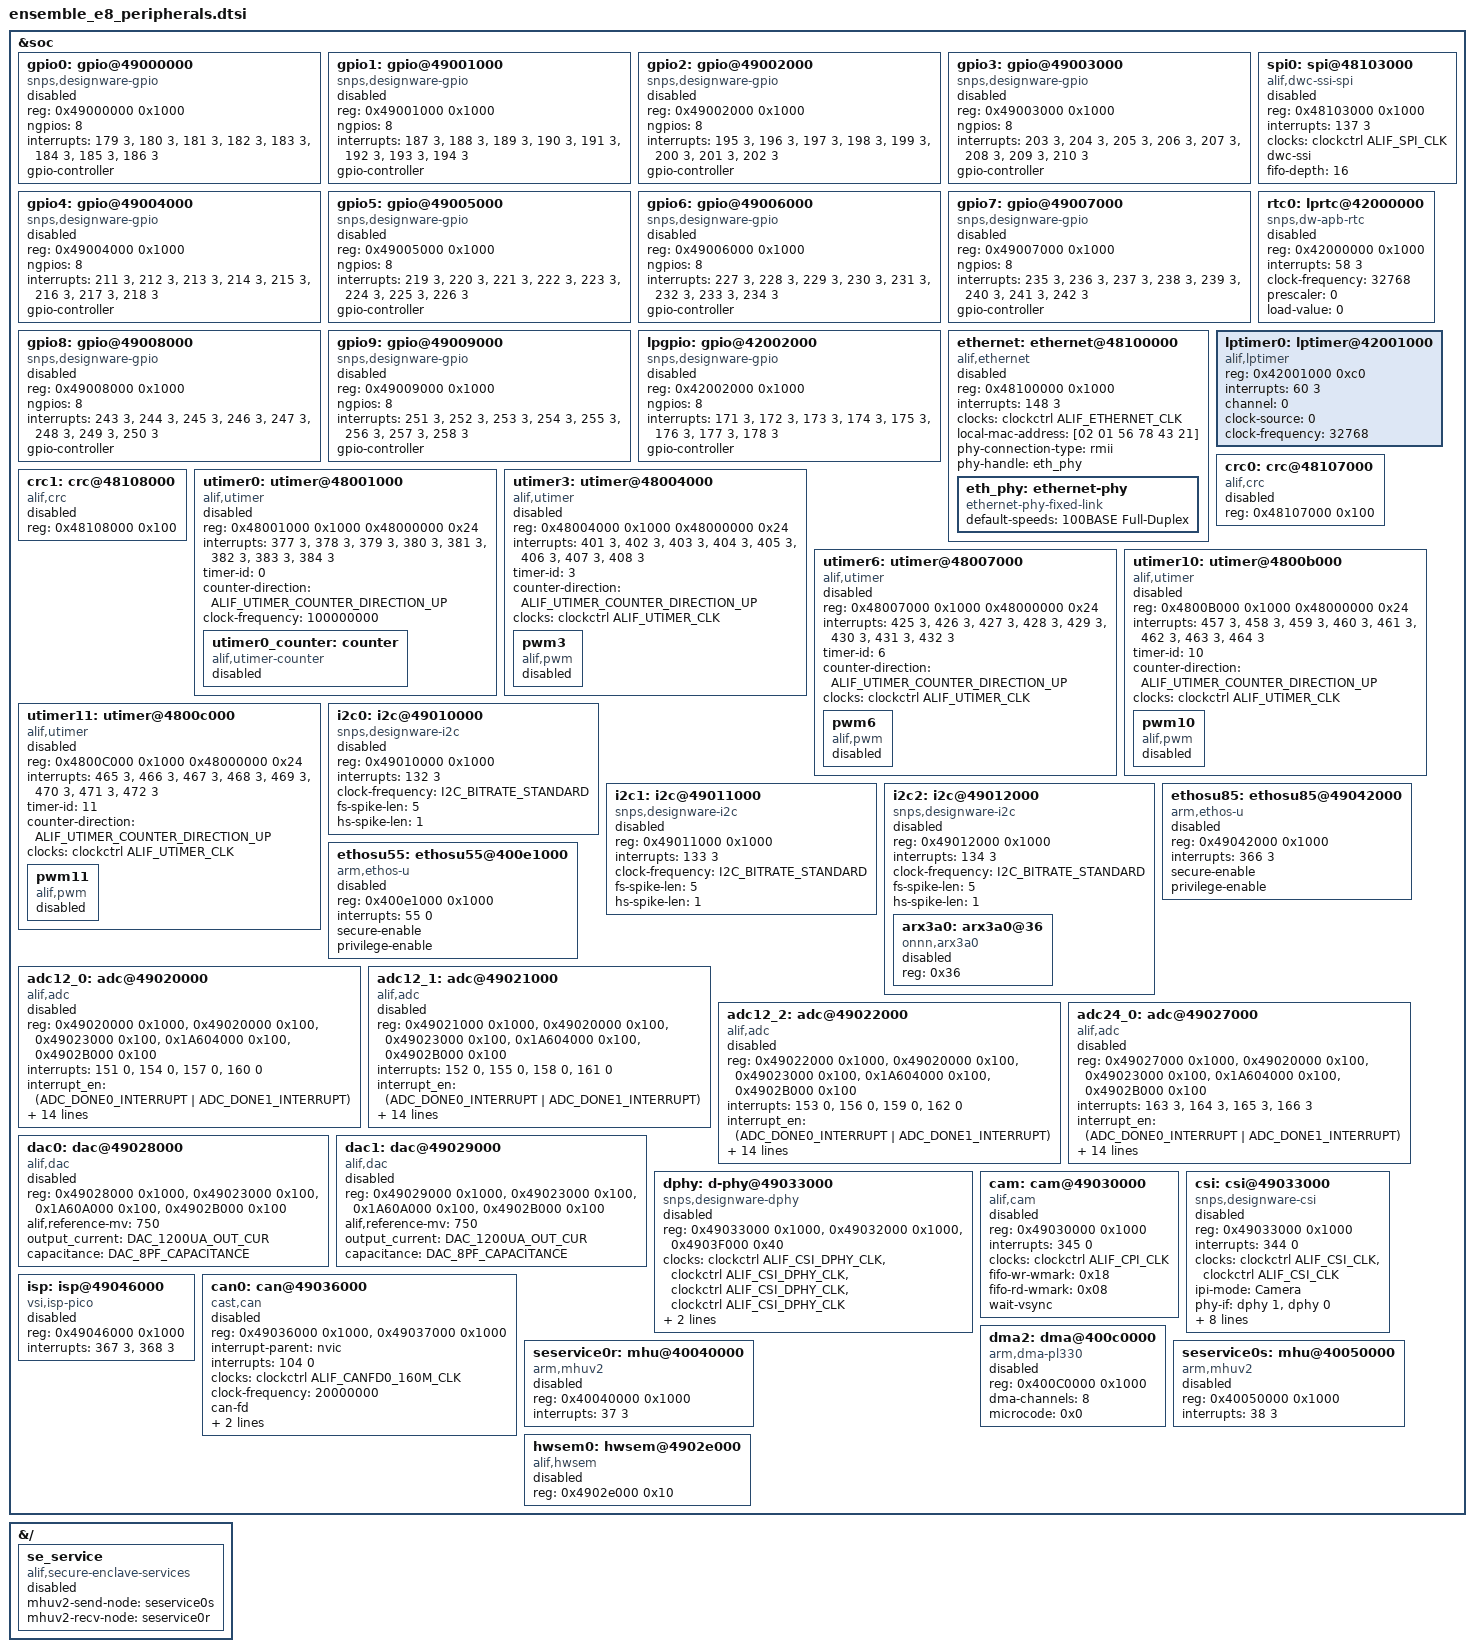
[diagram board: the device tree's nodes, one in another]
/*
 * Copyright (c) 2026 Alp Lab AB
 * SPDX-License-Identifier: Apache-2.0
 *
 * alp-sdk SoC-overlay for the Alif Ensemble E8 (AE822FA0E5597xx0).
 *
 * Upstream Zephyr v4.4's Alif SoC layer (dts/arm/alif/ensemble/) models only
 * UART + clocks + pinctrl + memory; the GPIO / I2C / SPI / Ethernet peripheral
 * nodes are absent.  Alif's peripherals are DesignWare (Synopsys) IP, for which
 * Zephyr already ships generic drivers (gpio_dw / i2c_dw / spi_dw / eth_dwmac),
 * so this overlay just *declares the nodes* with the `snps,designware-*`
 * compatibles + the SoC's reg / IRQ / clock; a board enables (status="okay")
 * the instances its carrier uses.
 *
 * reg/IRQ values are transcribed from Alif's Apache-2.0 zephyr_alif fork
 * (dts/arm/alif/ensemble/common/e1.dtsi) -- the same SoC, identical addresses.
 * The fork's ALIF_DEFAULT_IRQ_PRIORITY (not in upstream) is rendered here as a
 * literal priority 3 (the repo's default IRQ priority, matching the MHU nodes).
 *
 * Included by the alp_e1m_aen801_m55_{he,hp} boards via the alp-sdk dts_root
 * (`#include <alif/ensemble_e8_peripherals.dtsi>`).  vendor-ext, BENCH-UNVERIFIED.
 *
 * Populated (per ADR 0017 tiers): edge I2C i2c0/i2c1/i2c2 + GPIO
 * (snps,designware-* -- Tier-1 upstream-native); Ethernet (alif,ethernet glue
 * over the upstream eth_dwmac core -- Tier-1.5) + UTIMER PWM/counter
 * (alif,utimer over the Apache-2.0 hal_alif lib -- Tier-1.5); SPI0
 * (alif,dwc-ssi-spi -- Tier-2 interim).  The slave-only LPI2C0 housekeeping
 * trio (RTC/TMP/OPTIGA) is Tier-3 SE -- NO node here (see the LPI2C0 note).
 * The non-UART peripheral clock IDs upstream's alif-ensemble-clocks.h omits are
 * supplied, re-encoded for the upstream clockctrl, by the alp-sdk -ext header
 * included below.
 */

#include <zephyr/dt-bindings/clock/alif-ensemble-clocks-ext.h>
#include <zephyr/dt-bindings/timer/alif_utimer.h>
#include <zephyr/dt-bindings/i2c/i2c.h>
#include <zephyr/dt-bindings/adc/adc_alif.h>

&soc {
	/*
	 * DesignWare GPIO -- 10 general ports (gpio0..gpio9) + the LP-island
	 * port (lpgpio).  Each port is an independent 0x1000 register block with
	 * 8 pins and 8 per-pin interrupt lines.  gpio_dw needs no clocks and no
	 * pinctrl on the controller; the pad->GPIO mux is applied per-pin via the
	 * Alif pinctrl group on whichever node consumes the pin.
	 */
	gpio0: gpio@49000000 {
		compatible = "snps,designware-gpio";
		reg = <0x49000000 0x1000>;
		ngpios = <8>;
		interrupts = <179 3>, <180 3>, <181 3>, <182 3>,
			     <183 3>, <184 3>, <185 3>, <186 3>;
		gpio-controller;
		#gpio-cells = <2>;
		status = "disabled";
	};

	gpio1: gpio@49001000 {
		compatible = "snps,designware-gpio";
		reg = <0x49001000 0x1000>;
		ngpios = <8>;
		interrupts = <187 3>, <188 3>, <189 3>, <190 3>,
			     <191 3>, <192 3>, <193 3>, <194 3>;
		gpio-controller;
		#gpio-cells = <2>;
		status = "disabled";
	};

	gpio2: gpio@49002000 {
		compatible = "snps,designware-gpio";
		reg = <0x49002000 0x1000>;
		ngpios = <8>;
		interrupts = <195 3>, <196 3>, <197 3>, <198 3>,
			     <199 3>, <200 3>, <201 3>, <202 3>;
		gpio-controller;
		#gpio-cells = <2>;
		status = "disabled";
	};

	gpio3: gpio@49003000 {
		compatible = "snps,designware-gpio";
		reg = <0x49003000 0x1000>;
		ngpios = <8>;
		interrupts = <203 3>, <204 3>, <205 3>, <206 3>,
			     <207 3>, <208 3>, <209 3>, <210 3>;
		gpio-controller;
		#gpio-cells = <2>;
		status = "disabled";
	};

	gpio4: gpio@49004000 {
		compatible = "snps,designware-gpio";
		reg = <0x49004000 0x1000>;
		ngpios = <8>;
		interrupts = <211 3>, <212 3>, <213 3>, <214 3>,
			     <215 3>, <216 3>, <217 3>, <218 3>;
		gpio-controller;
		#gpio-cells = <2>;
		status = "disabled";
	};

	gpio5: gpio@49005000 {
		compatible = "snps,designware-gpio";
		reg = <0x49005000 0x1000>;
		ngpios = <8>;
		interrupts = <219 3>, <220 3>, <221 3>, <222 3>,
			     <223 3>, <224 3>, <225 3>, <226 3>;
		gpio-controller;
		#gpio-cells = <2>;
		status = "disabled";
	};

	gpio6: gpio@49006000 {
		compatible = "snps,designware-gpio";
		reg = <0x49006000 0x1000>;
		ngpios = <8>;
		interrupts = <227 3>, <228 3>, <229 3>, <230 3>,
			     <231 3>, <232 3>, <233 3>, <234 3>;
		gpio-controller;
		#gpio-cells = <2>;
		status = "disabled";
	};

	gpio7: gpio@49007000 {
		compatible = "snps,designware-gpio";
		reg = <0x49007000 0x1000>;
		ngpios = <8>;
		interrupts = <235 3>, <236 3>, <237 3>, <238 3>,
			     <239 3>, <240 3>, <241 3>, <242 3>;
		gpio-controller;
		#gpio-cells = <2>;
		status = "disabled";
	};

	gpio8: gpio@49008000 {
		compatible = "snps,designware-gpio";
		reg = <0x49008000 0x1000>;
		ngpios = <8>;
		interrupts = <243 3>, <244 3>, <245 3>, <246 3>,
			     <247 3>, <248 3>, <249 3>, <250 3>;
		gpio-controller;
		#gpio-cells = <2>;
		status = "disabled";
	};

	gpio9: gpio@49009000 {
		compatible = "snps,designware-gpio";
		reg = <0x49009000 0x1000>;
		ngpios = <8>;
		interrupts = <251 3>, <252 3>, <253 3>, <254 3>,
			     <255 3>, <256 3>, <257 3>, <258 3>;
		gpio-controller;
		#gpio-cells = <2>;
		status = "disabled";
	};

	lpgpio: gpio@42002000 {
		compatible = "snps,designware-gpio";
		reg = <0x42002000 0x1000>;
		ngpios = <8>;
		interrupts = <171 3>, <172 3>, <173 3>, <174 3>,
			     <175 3>, <176 3>, <177 3>, <178 3>;
		gpio-controller;
		#gpio-cells = <2>;
		status = "disabled";
	};

	/*
	 * LPI2C0 (0x43009000, the on-module "BRD_I2C" housekeeping bus on P7_4/P7_5,
	 * carrying OPTIGA / RV-3028 / TMP112) is DELIBERATELY NOT declared here.
	 * Per the TRM (§3.17.4) LPI2C0 is SLAVE-ONLY (the SoC is a slave at the
	 * hardcoded address 0x40); the M55 cannot master it, so an alp-sdk I2C
	 * master node would be a dead end.  That trio is ADR 0017 Tier-3: the
	 * Secure Enclave masters the bus and the reads are surfaced through Alif SE
	 * services as a portable board-info/manifest API (tasks #16/#17).  The
	 * removed alif,lpi2c driver (task #21) was the master-TX-only dead end.
	 * A next-rev board moves the housekeeping bus to a master-capable I2C
	 * (LPI2C0 -> I2C0 on P7_0/P7_1 -- task #11).
	 */

	/*
	 * Synopsys DesignWare MAC (GMAC) -- the Ensemble RMII Ethernet MAC,
	 * backing the UPSTREAM eth_dwmac core via the alp-sdk Alif glue
	 * (drivers/ethernet/eth_dwmac_alif_ensemble.c, compatible "alif,ethernet").
	 * reg/IRQ transcribed from the fork's e1.dtsi (ethernet@48100000, IRQ 148);
	 * the ALIF_ETHERNET_CLK id is synthesized in the UPSTREAM clock encoding
	 * (see alif-ensemble-clocks-ext.h -- the fork's packed value would target
	 * the wrong clock block).
	 *
	 * First bring-up uses a FIXED-LINK PHY: upstream Zephyr v4.4 ships no
	 * snps,designware-mdio driver, so the on-SoM TI DP83825I (RMII, 100/full)
	 * runs unmanaged.  A board enables this node (status="okay") + supplies
	 * pinctrl_eth (the RMII pin group) + a real local-mac-address.
	 *
	 * ADR 0017 Tier-1.5 (in-tree glue over the UPSTREAM core; kept, not
	 * fork-consumed -- the fork forked the core).  INTERIM until E8 bench.
	 *
	 * BENCH-UNVERIFIED + bench follow-up: the RMII 50 MHz ref-clock on the
	 * E1M-AEN801 comes from an on-module oscillator into P11_0 (clock-in mode);
	 * the upstream alif clock driver has NO path to program ETH_CTRL_REG's
	 * ref-clk-source select, so whether silicon needs that bit set before the
	 * MAC sees a clock is unconfirmed (do NOT invent it).
	 */
	ethernet: ethernet@48100000 {
		compatible = "alif,ethernet", "snps,designware-ethernet";
		reg = <0x48100000 0x1000>;
		interrupts = <148 3>;
		clocks = <&clockctrl ALIF_ETHERNET_CLK>;
		local-mac-address = [02 01 56 78 43 21];
		phy-connection-type = "rmii";
		phy-handle = <&eth_phy>;
		/* pinctrl-0 + pinctrl-names supplied by the enabling board overlay
		 * (RMII pin group); omitted here so the disabled node validates. */
		status = "disabled";

		eth_phy: ethernet-phy {
			compatible = "ethernet-phy-fixed-link";
			status = "okay";
			default-speeds = "100BASE Full-Duplex";
		};
	};

	/*
	 * DesignWare DWC_ssi SPI0 (AHB, always-on domain).  Driven by the alp-sdk
	 * vendored DWC-SSI driver (drivers/spi/spi_dw_alif.c, compatible
	 * "alif,dwc-ssi-spi") -- NOT upstream's "snps,designware-spi" spi_dw, which
	 * drives the DW-apb-SSI register layout (wrong CTRLR0 bit positions for this
	 * IP).  The `dwc-ssi` flag selects the DWC_ssi layout.  reg/IRQ from the
	 * fork's e1.dtsi; ALIF_SPI_CLK is a frequency-only dummy (no gate reg).
	 *
	 * ADR 0017 Tier-2 (fork-driver copy; hal_alif has no SSI lib) -- INTERIM,
	 * retires onto the fork once spi0 is repointed + bench-verified (task #21).
	 *
	 * BENCH-UNVERIFIED.  Netlist-grounded as the customer-facing edge SPI master
	 * (SoC P5_x); a board enables it (status="okay") + supplies pinctrl + the CS
	 * scheme (HW-SS vs cs-gpios is a bench unknown -- do not hard-code).  spi1
	 * (0x48104000) is the on-SoM CC3501E Wi-Fi link (GPIO-CS), not a free edge
	 * bus -- not declared here.  fifo-depth/max-xfer-size/rx-delay carry safe
	 * overridable binding defaults; override per the Alif TRM.
	 */
	spi0: spi@48103000 {
		compatible = "alif,dwc-ssi-spi";
		#address-cells = <1>;
		#size-cells = <0>;
		reg = <0x48103000 0x1000>;
		interrupts = <137 3>;
		clocks = <&clockctrl ALIF_SPI_CLK>;
		dwc-ssi;
		fifo-depth = <16>;
		status = "disabled";
	};

	/*
	 * LPRTC -- the always-on Synopsys DesignWare APB RTC at lprtc@42000000.
	 * Bound by the alp-sdk Tier-2 driver counter_dw_rtc.c (compatible
	 * "snps,dw-apb-rtc") as a Zephyr COUNTER device: a free-running 32-bit
	 * up-counter (CCVR) with ONE compare/alarm channel (CMR), clocked at
	 * 32768 Hz from the VBAT-domain LF source.  This is NOT a calendar RTC --
	 * it has no battery-backed date/time registers, so it does NOT satisfy the
	 * alp_rtc_* calendar surface as-is (the alp on-silicon RTC backend binds
	 * the Zephyr RTC *class* via the alp-rtc alias, which will not bind a
	 * counter; a counter->calendar shim backend is still TBD).  Surfaced to
	 * app code as an alp_counter via the alp-counter alias instead.
	 *
	 * reg/IRQ/clock transcribed VERBATIM from the Apache-2.0 zephyr_alif fork
	 * e1.dtsi (rtc0: lprtc@42000000; reg 0x42000000/0x1000; IRQ 58; 32768 Hz;
	 * prescaler 0; load-value 0).  The fork's ALIF_DEFAULT_IRQ_PRIORITY is
	 * rendered here as the repo's literal priority 3 (as the rest of this
	 * overlay does).
	 *
	 * CLOCK-GATE NOTE (BENCH-UNVERIFIED): the fork's SoC layer enables the
	 * LPRTC clock from VBAT when this node is okay (soc_common.c writes
	 * VBAT_LPRTC0_CLK_EN, 0x1A609010, iff rtc0 is okay).  alp-sdk builds
	 * against upstream Zephyr v4.4, whose ensemble soc.c does NOT do this
	 * write, and the driver does not write VBAT either -- so on this build path
	 * the gate is enabled by no visible code.  Confirm on the E8 bench whether
	 * the always-on VBAT domain already has it running (read CCVR; if it never
	 * advances, the VBAT gate is the cause).  Tier-2, INTERIM, task #21.
	 */
	rtc0: lprtc@42000000 {
		compatible = "snps,dw-apb-rtc";
		reg = <0x42000000 0x1000>;
		interrupts = <58 3>;
		clock-frequency = <32768>;
		prescaler = <0>;
		load-value = <0>;
		status = "disabled";
	};

	/*
	 * LPTIMER -- the always-on Alif Ensemble low-power timer at
	 * lptimer@42001000 (a DISTINCT IP from the LPRTC above and the UTIMER
	 * below).  The block holds four independent 32-bit DOWN-counters
	 * (channels 0..3), each clocked from the VBAT-domain LF source and each
	 * with its own NVIC line firing on underflow.  Bound by the alp-sdk
	 * Tier-1.5 driver counter_alif_lptimer.c (compatible "alif,lptimer") as a
	 * Zephyr COUNTER device; surfaced to app code as an alp_counter via the
	 * alp-counter alias.
	 *
	 * reg base + the four channel IRQs are transcribed VERBATIM from the Alif
	 * DFP for the E8 part AE822FA0E5597 (Device/soc/AE822FA0E5597/include/
	 * rtss_he/soc.h: LPTIMER_BASE 0x42001000, size 0xC0; IRQn LPTIMER0..3 =
	 * 60..63).  This single node selects channel 0 (IRQ 60); to use another
	 * channel, set `channel` + its matching `interrupts` (ch1=61, ch2=62,
	 * ch3=63).  IRQ priority is the repo literal 3 (as the rest of this
	 * overlay does).
	 *
	 * clock-source 0 = 32 kHz (Alif DFP sys_ctrl_lptimer.h LPTIMER_CLK_SRC);
	 * clock-frequency 32768 must match it.  These select the VBAT
	 * TIMER_CLKSEL field only; they do not change whether the count advances.
	 *
	 * CLOCK NOTE (BENCH-UNVERIFIED): the driver selects this channel's clock
	 * in the always-on VBAT TIMER_CLKSEL (0x1A609004) from the `clock-source`
	 * prop.  Whether the chosen VBAT LF source is itself running on the
	 * alp-sdk upstream-Zephyr build path is bench-TBD (read CURRENTVAL; if it
	 * never advances, the source clock is the cause).  Tier-1.5, INTERIM,
	 * task #21.
	 */
	lptimer0: lptimer@42001000 {
		compatible = "alif,lptimer";
		reg = <0x42001000 0xc0>;
		interrupts = <60 3>;
		channel = <0>;
		clock-source = <0>;       /* 0 = 32 kHz VBAT LF source */
		clock-frequency = <32768>;
	};

	/*
	 * CRC engine -- the Alif Ensemble hardware CRC accelerator (two
	 * instances).  Bound by the alp-sdk clean-room driver crc_alif.c
	 * (compatible "alif,crc"), which implements the UPSTREAM Zephyr v4.4 CRC
	 * class API (crc_begin/update/finish over struct crc_ctx).  Polled,
	 * memory-mapped block -- no interrupt line (the DFP CRC engine exposes no
	 * dedicated IRQ; only an optional DMA path this driver does not use), so
	 * the node carries reg only.
	 *
	 * reg transcribed VERBATIM (value-only, clean-room) from the Alif DFP SoC
	 * header (AE822FA0E5597 rtss_he soc.h: CRC0_BASE 0x48107000,
	 * CRC1_BASE 0x48108000; CRC_Type size 0x100).  Disabled by default; a
	 * board / example enables an instance (status = "okay").  ADR 0017
	 * Tier-1.5 (in-tree-thin over the silicon).  BENCH-UNVERIFIED, task #21.
	 */
	crc0: crc@48107000 {
		compatible = "alif,crc";
		reg = <0x48107000 0x100>;
		status = "disabled";
	};

	crc1: crc@48108000 {
		compatible = "alif,crc";
		reg = <0x48108000 0x100>;
		status = "disabled";
	};

	/*
	 * UTIMER -- Alif Universal Timer.  The parent "alif,utimer" node is an
	 * unbound container (reg = per-timer block 0x48001000+id*0x1000 + the shared
	 * global block 0x48000000); a child binds the actual class driver:
	 *   - "alif,pwm"            -> zephyr/drivers/pwm/pwm_alif_utimer.c
	 *   - "alif,utimer-counter" -> zephyr/drivers/counter/counter_alif_utimer.c
	 * reg/IRQ transcribed VERBATIM from the Apache-2.0 zephyr_alif fork e1*.dtsi
	 * (utimer0 IRQ377-384; utimer3 401-408; utimer6 425-432; utimer10 457-464;
	 * utimer11 465-472).  clock-frequency is a PLACEHOLDER tick rate (confirm vs
	 * the Alif TRM at bench bring-up; only scales us<->ticks, not register
	 * programming).  A board enables a node + its child + the alp-{pwm,counter}
	 * alias.  ADR 0017 Tier-1.5 (thin Zephyr drivers over the Apache-2.0 hal_alif
	 * alif_utimer_* register library; the fork ships UTIMER bindings only, no
	 * driver -- so there is no Tier-2 path to retire onto).  INTERIM until E8
	 * bench, then promotes to permanent.  BENCH-UNVERIFIED.
	 *
	 * utimer0 backs the portable alp_counter surface; utimer3/6/10/11 back the
	 * eight E1M PWM pads.
	 */
	utimer0: utimer@48001000 {
		compatible = "alif,utimer";
		reg = <0x48001000 0x1000 0x48000000 0x24>;
		reg-names = "timer", "global";
		interrupts = <377 3>, <378 3>, <379 3>, <380 3>,
			     <381 3>, <382 3>, <383 3>, <384 3>;
		interrupt-names = "comp_capt_a", "comp_capt_b",
				  "comp_a_buf1", "comp_a_buf2", "comp_b_buf1",
				  "comp_b_buf2", "underflow", "overflow";
		timer-id = <0>;
		counter-direction = <ALIF_UTIMER_COUNTER_DIRECTION_UP>;
		clock-frequency = <100000000>; /* placeholder; confirm vs TRM */
		status = "disabled";

		utimer0_counter: counter {
			compatible = "alif,utimer-counter";
			status = "disabled";
		};
	};

	utimer3: utimer@48004000 {
		compatible = "alif,utimer";
		reg = <0x48004000 0x1000 0x48000000 0x24>;
		reg-names = "timer", "global";
		interrupts = <401 3>, <402 3>, <403 3>, <404 3>,
			     <405 3>, <406 3>, <407 3>, <408 3>;
		timer-id = <3>;
		counter-direction = <ALIF_UTIMER_COUNTER_DIRECTION_UP>;
		clocks = <&clockctrl ALIF_UTIMER_CLK>;
		status = "disabled";

		pwm3: pwm3 {
			compatible = "alif,pwm";
			#pwm-cells = <3>;
			status = "disabled";
		};
	};

	utimer6: utimer@48007000 {
		compatible = "alif,utimer";
		reg = <0x48007000 0x1000 0x48000000 0x24>;
		reg-names = "timer", "global";
		interrupts = <425 3>, <426 3>, <427 3>, <428 3>,
			     <429 3>, <430 3>, <431 3>, <432 3>;
		timer-id = <6>;
		counter-direction = <ALIF_UTIMER_COUNTER_DIRECTION_UP>;
		clocks = <&clockctrl ALIF_UTIMER_CLK>;
		status = "disabled";

		pwm6: pwm6 {
			compatible = "alif,pwm";
			#pwm-cells = <3>;
			status = "disabled";
		};
	};

	utimer10: utimer@4800b000 {
		compatible = "alif,utimer";
		reg = <0x4800B000 0x1000 0x48000000 0x24>;
		reg-names = "timer", "global";
		interrupts = <457 3>, <458 3>, <459 3>, <460 3>,
			     <461 3>, <462 3>, <463 3>, <464 3>;
		timer-id = <10>;
		counter-direction = <ALIF_UTIMER_COUNTER_DIRECTION_UP>;
		clocks = <&clockctrl ALIF_UTIMER_CLK>;
		status = "disabled";

		pwm10: pwm10 {
			compatible = "alif,pwm";
			#pwm-cells = <3>;
			status = "disabled";
		};
	};

	utimer11: utimer@4800c000 {
		compatible = "alif,utimer";
		reg = <0x4800C000 0x1000 0x48000000 0x24>;
		reg-names = "timer", "global";
		interrupts = <465 3>, <466 3>, <467 3>, <468 3>,
			     <469 3>, <470 3>, <471 3>, <472 3>;
		timer-id = <11>;
		counter-direction = <ALIF_UTIMER_COUNTER_DIRECTION_UP>;
		clocks = <&clockctrl ALIF_UTIMER_CLK>;
		status = "disabled";

		pwm11: pwm11 {
			compatible = "alif,pwm";
			#pwm-cells = <3>;
			status = "disabled";
		};
	};

	/*
	 * Synopsys DesignWare I2C (DW_apb_i2c) -- the customer-facing EDGE I2C
	 * master buses on the E1M connector.  Bound by UPSTREAM Zephyr v4.4 i2c_dw
	 * (compatible "snps,designware-i2c"): full controller-mode read + write +
	 * repeated-START -- the master capability the slave-only LPI2C0 lacks.
	 * i2c_dw consumes only reg / interrupts / clock-frequency (= the I2C BUS
	 * speed, NOT an input clock); it does NOT read a `clocks` phandle and calls
	 * no clock_control op, so no clock-id is needed.  reg/IRQ (132/133) + the
	 * spike-filter tuning transcribed from the Apache-2.0 zephyr_alif fork
	 * e1.dtsi.  A board enables an instance (status="okay") + supplies pinctrl-0
	 * + the alp-i2cN alias.  ADR 0017 Tier-1 (upstream-native), BENCH-UNVERIFIED.
	 *
	 * NOTE: i2c0/i2c1 reach EDGE pads.  The on-module 24C128 EEPROM is on i2c2
	 * below (bridge/DNP-selected, P5_6/P5_7).  The on-module RTC/TMP112/OPTIGA
	 * sit on the slave-only LPI2C0 (P7_4/P7_5) this rev and are NOT reachable as
	 * an I2C master -- they are Tier-3 (Alif SE services); see the LPI2C0 note
	 * above + task #11 (next-rev move to a master-capable I2C).
	 */
	i2c0: i2c@49010000 {
		compatible = "snps,designware-i2c";
		#address-cells = <1>;
		#size-cells = <0>;
		reg = <0x49010000 0x1000>;
		interrupts = <132 3>;
		clock-frequency = <I2C_BITRATE_STANDARD>;
		fs-spike-len = <5>;
		hs-spike-len = <1>;
		status = "disabled";
	};

	i2c1: i2c@49011000 {
		compatible = "snps,designware-i2c";
		#address-cells = <1>;
		#size-cells = <0>;
		reg = <0x49011000 0x1000>;
		interrupts = <133 3>;
		clock-frequency = <I2C_BITRATE_STANDARD>;
		fs-spike-len = <5>;
		hs-spike-len = <1>;
		status = "disabled";
	};

	/*
	 * I2C2 -- carries the on-module 24C128 EEPROM (the Alp manifest) on the
	 * E1M-AEN801: the EEPROM's interface is selected by bridge/DNP resistors to
	 * this DesignWare master bus (SoC pins P5_6 SCL_C / P5_7 SDA_C), NOT the
	 * slave-only LPI2C0.  Full master read+write via upstream i2c_dw.  reg/IRQ
	 * are authoritative from the AE822 DFP device header (I2C2_BASE 0x49012000,
	 * I2C2_IRQ_IRQn 134).  A board enables it + supplies pinctrl_i2c2 (P5_6/7) +
	 * the alp-i2cN alias.  vendor-ext (upstream driver), BENCH-UNVERIFIED.
	 */
	i2c2: i2c@49012000 {
		compatible = "snps,designware-i2c";
		#address-cells = <1>;
		#size-cells = <0>;
		reg = <0x49012000 0x1000>;
		interrupts = <134 3>;
		clock-frequency = <I2C_BITRATE_STANDARD>;
		fs-spike-len = <5>;
		hs-spike-len = <1>;
		status = "disabled";
	};

	/*
	 * Arm Ethos-U NPUs.  The E8 (AE822) has THREE Ethos-U NPUs total -- 1x
	 * Ethos-U85 (256 MAC) + 2x Ethos-U55 (256 + 128 MAC), per the alif_e8_dk doc.
	 * All are bound by the UPSTREAM Zephyr driver (drivers/misc/ethos_u/
	 * ethos_u_arm.c, compatible "arm,ethos-u") over Arm's Apache-2.0
	 * ethos-u-core-driver (the `hal_ethos_u` Zephyr module) -- pure Tier-1
	 * (upstream + a standard Zephyr HAL module), no vendored code.  But only TWO
	 * device-tree nodes are needed, because of how the NPUs are addressed (reg/IRQ
	 * from the Apache-2.0 zephyr_alif fork: e4_e6_e8.dtsi for U85, e1.dtsi for U55):
	 *
	 *   - ethosu85@49042000 (IRQ 366): the high-end Ethos-U85, 256 MAC/cycle, in
	 *     the GLOBAL peripheral space -- one physical NPU, reachable from a core
	 *     (the RTSS-HE on this SoM) at this global address.  The E8's headline
	 *     ML/GenAI accelerator.
	 *   - ethosu55@400e1000 (IRQ 55): the Ethos-U55, but at the RTSS-core-LOCAL
	 *     address (0x400e1000 is core-private; the hal_alif driver does a
	 *     local->global remap).  The "2x U55" are NOT two addressable nodes -- they
	 *     are the per-core-local NPUs that alias to the SAME local address: the
	 *     RTSS-HP cluster's U55 is 256 MAC (alif_e8_dk HP defconfig pins
	 *     CONFIG_ARM_ETHOS_U55_256), the RTSS-HE cluster's U55 is 128 MAC.  Each
	 *     M55 only sees its OWN at 0x400e1000, so a single node suffices (exactly
	 *     as Alif's own fork dtsi does); the MAC count is core-specific, picked via
	 *     CONFIG_ARM_ETHOS_U55_{256,128} by whichever board/core builds.  (The
	 *     e1c/e1 SoC variants have ONLY this local U55 -- no U85.)
	 *
	 * A board enables the node(s) it uses + selects CONFIG_ETHOS_U +
	 * CONFIG_ETHOS_U_ARM + the per-NPU config (CONFIG_ETHOS_U85_256 /
	 * CONFIG_ARM_ETHOS_U55_*) and adds `hal_ethos_u` as a Zephyr module.  ETHOS_U_NPU
	 * is one Kconfig `choice`, so the U85 and the U55 are SEPARATE firmware builds.
	 * Inference then needs a Vela-compiled model + tensor arena.
	 *
	 * BENCH-VALIDATED at the driver level on real E8 (M55-HE) -- BOTH NPUs the HE
	 * core can reach: ethosu_init() soft-resets + registers each, device_is_ready()
	 * true.  U85 @0x49042000 NPU_REG_ID 0x20007001; HE-local U55 @0x400e1000
	 * NPU_REG_ID 0x10104201 (distinct IDs = distinct silicon).  The HP-local U55
	 * (256 MAC) is only reachable from the RTSS-HP core, so it is not exercised here.
	 */
	ethosu85: ethosu85@49042000 {
		compatible = "arm,ethos-u";
		reg = <0x49042000 0x1000>;
		interrupts = <366 3>;
		secure-enable;
		privilege-enable;
		status = "disabled";
	};

	ethosu55: ethosu55@400e1000 {
		compatible = "arm,ethos-u";
		reg = <0x400e1000 0x1000>;
		interrupts = <55 0>;
		secure-enable;
		privilege-enable;
		status = "disabled";
	};

	/*
	 * ADC -- Alif Ensemble analog-to-digital converters: three 12-bit SAR ADCs
	 * (adc12_0..2) + one 24-bit sigma-delta ADC (adc24_0).  Driven by the alp-sdk
	 * vendored fork driver (zephyr/drivers/adc/adc_alif.c, compatible "alif,adc")
	 * over the hal_alif analog_ctrl VREF library (CONFIG_ADC_ALIF selects
	 * USE_ALIF_HAL_ANALOG).  reg / reg-names / IRQs / config properties are
	 * transcribed VERBATIM from the Apache-2.0 zephyr_alif fork e1.dtsi
	 * (ensemble/common/e1.dtsi adc0..adc24):
	 *
	 *   reg-names: "adc_reg"   = per-instance ADC block (0x49020000 + id*0x1000;
	 *                            adc24 at 0x49027000)
	 *              "analog_reg"= shared ADC1 analog-control base 0x49020000
	 *              "comp_reg"  = shared comparator block 0x49023000
	 *              "aon_regs"  = always-on PMU_PERIPH block 0x1A604000
	 *              "adc_vref"  = shared ADC VREF block 0x4902B000
	 *   IRQs (done0,done1,comp_a,comp_b):
	 *              adc12_0  151,154,157,160 ; adc12_1 152,155,158,161
	 *              adc12_2  153,156,159,162 ; adc24_0 163,164,165,166
	 *   interrupt_en = DONE0|DONE1 (single-shot completion fires on DONE1).
	 *
	 * No pinctrl-0: ADC inputs are direct analog pads (the driver applies
	 * pinctrl only IF the node carries it -- IF_ENABLED on pinctrl_0).  A board
	 * enables an instance (status="okay"), sets the alp-adcN alias for the
	 * portable backend, and -- for differential / specific channels -- may add a
	 * pinctrl group per the Alif TRM.
	 *
	 * ADR 0017 Tier-2 (fork-driver copy; hal_alif has no ADC class driver) --
	 * INTERIM, retires onto the fork once the nodes are repointed +
	 * bench-verified (task #21).  BENCH-UNVERIFIED.
	 */
	adc12_0: adc@49020000 {
		compatible = "alif,adc";
		/* adc-controller.yaml (via alif,adc.yaml) requires #io-channel-cells;
		 * #address-cells/#size-cells enable the io-channels `channel@N` children. */
		#address-cells = <1>;
		#size-cells = <0>;
		#io-channel-cells = <1>;
		reg = <0x49020000 0x1000>,
		      <0x49020000 0x100>,
		      <0x49023000 0x100>,
		      <0x1A604000 0x100>,
		      <0x4902B000 0x100>;
		reg-names = "adc_reg", "analog_reg", "comp_reg", "aon_regs", "adc_vref";
		interrupts = <151 0>, <154 0>, <157 0>, <160 0>;
		interrupt-names = "done0", "done1", "comp_a", "comp_b";
		interrupt_en = <(ADC_DONE0_INTERRUPT | ADC_DONE1_INTERRUPT)>;
		comparator_threshold_a = <0x01>;
		comparator_threshold_b = <0x01>;
		comparator_threshold_comparison = "ABOVE_THRESHOLD_A_AND_B";
		sample-width = <16>;
		clock_div = <2>;
		avg_sample_num = <256>;
		shift_n_bits = <8>;
		shift_direction = "RIGHT_SHIFT";
		comparator_bias = "2.5_MS/s";
		driver_instance = "ADC_INSTANCE_ADC12_0";
		adc_channel_scan = "SINGLE_CHANNEL_SCAN";
		adc_conversion_mode = "SINGLE_SHOT_CONVERSION";
		pga_gain = "ADC_PGA_GAIN_0_DB";
		status = "disabled";
	};

	adc12_1: adc@49021000 {
		compatible = "alif,adc";
		#address-cells = <1>;
		#size-cells = <0>;
		#io-channel-cells = <1>;
		reg = <0x49021000 0x1000>,
		      <0x49020000 0x100>,
		      <0x49023000 0x100>,
		      <0x1A604000 0x100>,
		      <0x4902B000 0x100>;
		reg-names = "adc_reg", "analog_reg", "comp_reg", "aon_regs", "adc_vref";
		interrupts = <152 0>, <155 0>, <158 0>, <161 0>;
		interrupt-names = "done0", "done1", "comp_a", "comp_b";
		interrupt_en = <(ADC_DONE0_INTERRUPT | ADC_DONE1_INTERRUPT)>;
		comparator_threshold_a = <0x01>;
		comparator_threshold_b = <0x01>;
		comparator_threshold_comparison = "ABOVE_THRESHOLD_A_AND_B";
		sample-width = <16>;
		clock_div = <2>;
		avg_sample_num = <256>;
		shift_n_bits = <8>;
		shift_direction = "RIGHT_SHIFT";
		comparator_bias = "2.5_MS/s";
		driver_instance = "ADC_INSTANCE_ADC12_1";
		adc_channel_scan = "SINGLE_CHANNEL_SCAN";
		adc_conversion_mode = "SINGLE_SHOT_CONVERSION";
		pga_gain = "ADC_PGA_GAIN_0_DB";
		status = "disabled";
	};

	adc12_2: adc@49022000 {
		compatible = "alif,adc";
		#address-cells = <1>;
		#size-cells = <0>;
		#io-channel-cells = <1>;
		reg = <0x49022000 0x1000>,
		      <0x49020000 0x100>,
		      <0x49023000 0x100>,
		      <0x1A604000 0x100>,
		      <0x4902B000 0x100>;
		reg-names = "adc_reg", "analog_reg", "comp_reg", "aon_regs", "adc_vref";
		interrupts = <153 0>, <156 0>, <159 0>, <162 0>;
		interrupt-names = "done0", "done1", "comp_a", "comp_b";
		interrupt_en = <(ADC_DONE0_INTERRUPT | ADC_DONE1_INTERRUPT)>;
		comparator_threshold_a = <0x01>;
		comparator_threshold_b = <0x01>;
		comparator_threshold_comparison = "ABOVE_THRESHOLD_A_AND_B";
		sample-width = <16>;
		clock_div = <2>;
		avg_sample_num = <256>;
		shift_n_bits = <8>;
		shift_direction = "RIGHT_SHIFT";
		comparator_bias = "2.5_MS/s";
		driver_instance = "ADC_INSTANCE_ADC12_2";
		adc_channel_scan = "SINGLE_CHANNEL_SCAN";
		adc_conversion_mode = "SINGLE_SHOT_CONVERSION";
		pga_gain = "ADC_PGA_GAIN_0_DB";
		status = "disabled";
	};

	adc24_0: adc@49027000 {
		compatible = "alif,adc";
		#address-cells = <1>;
		#size-cells = <0>;
		#io-channel-cells = <1>;
		reg = <0x49027000 0x1000>,
		      <0x49020000 0x100>,
		      <0x49023000 0x100>,
		      <0x1A604000 0x100>,
		      <0x4902B000 0x100>;
		reg-names = "adc_reg", "analog_reg", "comp_reg", "aon_regs", "adc_vref";
		interrupts = <163 3>, <164 3>, <165 3>, <166 3>;
		interrupt-names = "done0", "done1", "comp_a", "comp_b";
		interrupt_en = <(ADC_DONE0_INTERRUPT | ADC_DONE1_INTERRUPT)>;
		comparator_threshold_a = <0x01>;
		comparator_threshold_b = <0x01>;
		comparator_threshold_comparison = "ABOVE_THRESHOLD_A_AND_B";
		clock_div = <2>;
		avg_sample_num = <256>;
		shift_n_bits = <8>;
		shift_direction = "RIGHT_SHIFT";
		adc24_output_rate = "1KS/s";
		adc24_bias = "8.75uA";
		driver_instance = "ADC_INSTANCE_ADC24_0";
		adc_channel_scan = "SINGLE_CHANNEL_SCAN";
		adc_conversion_mode = "SINGLE_SHOT_CONVERSION";
		pga_gain = "ADC_PGA_GAIN_0_DB";
		status = "disabled";
	};

	/*
	 * DAC -- Alif Ensemble DAC12: two 12-bit current-output DACs (dac0, dac1).
	 * Driven by the alp-sdk vendored fork driver (zephyr/drivers/dac/dac_alif.c,
	 * compatible "alif,dac") over the hal_alif analog_ctrl VREF library
	 * (CONFIG_DAC_ALIF selects USE_ALIF_HAL_ANALOG, shared with ADC_ALIF).  reg /
	 * reg-names / config properties are transcribed VERBATIM from the Apache-2.0
	 * zephyr_alif fork e1.dtsi (ensemble/common/e1.dtsi dac0/dac1):
	 *
	 *   reg-names: "dac_reg"  = per-instance DAC control block
	 *                           (dac0 0x49028000, dac1 0x49029000)
	 *              "cmp_reg"  = shared comparator block 0x49023000 (VREF control)
	 *              "vbat_reg" = always-on VBAT/analog block 0x1A60A000 (LDO+BG)
	 *              "adc_vref" = shared ADC/DAC VREF block 0x4902B000 (mapped by
	 *                           the driver ONLY under CONFIG_ANALOG_ALIASING; it is
	 *                           carried here for completeness, like the ADC nodes,
	 *                           and ignored otherwise)
	 *
	 * NO `interrupts`: the Alif DAC is a write-only IP with no IRQ -- the fork
	 * dac nodes carry none and the driver has no IRQ_CONNECT.  (Sourced from the
	 * fork driver + e1.dtsi; do NOT invent an IRQ.)
	 *
	 * NO pinctrl-0: the fork nodes reference &pinctrl_dac0/&pinctrl_dac1 (the DAC
	 * analog output pads -- dac0 = P2_2, dac1 = P2_3 per the bench notes), but
	 * those pinctrl groups are not defined in this tree.  The driver applies
	 * pinctrl only IF the node carries it (IF_ENABLED on pinctrl_0), so the nodes
	 * are left pinctrl-less; a board that needs the pad muxed adds the group per
	 * the Alif TRM.  The P2_2 / P2_3 pad mapping is a BENCH NOTE, not yet a
	 * verified pinctrl group.
	 *
	 * alif,reference-mv = DAC12 full-scale VREF in mV, consumed by the portable
	 * backend's mv->code conversion (the E8 DAC12 full-scale is the DAC VREF, NOT
	 * 3.3 V).  Set to 750: the dac_alif driver programs the DAC12 reference field
	 * to DAC12_VREF_CONT = 0x4 (dac_alif.c CMP_COMP_REG2_DAC12_VREF_CONT =
	 * (0x4U << 17), == hal_alif analog_ctrl.h:41 #define DAC12_VREF_CONT
	 * (0x4U << 17)), and the analog_ctrl.h:31-40 DAC12 reference table reads
	 * code 0x4 (100b) = 0.750 V.  So the mv->code divisor MUST be 750 to match
	 * the reference the silicon is actually programmed to (the old 900 was a
	 * wrong placeholder, not just unverified).  This is the REGISTER reference,
	 * verified vs hal_alif; the ABSOLUTE on-pad mV (load/buffer/trim) is still a
	 * TRM/bench unknown.  BENCH-UNVERIFIED (absolute pad mV).
	 *
	 * ADR 0017 Tier-2 (fork-driver copy; hal_alif has no DAC class driver) --
	 * INTERIM, retires onto the fork once the nodes are repointed +
	 * bench-verified (task #21).  BENCH-UNVERIFIED.
	 */
	dac0: dac@49028000 {
		compatible = "alif,dac";
		reg = <0x49028000 0x1000>,
		      <0x49023000 0x100>,
		      <0x1A60A000 0x100>,
		      <0x4902B000 0x100>;
		reg-names = "dac_reg", "cmp_reg", "vbat_reg", "adc_vref";
		alif,reference-mv = <750>; /* DAC12_VREF_CONT=0x4 -> 0.750 V (analog_ctrl.h:41) */
		output_current = "DAC_1200UA_OUT_CUR";
		capacitance = "DAC_8PF_CAPACITANCE";
		status = "disabled";
	};

	dac1: dac@49029000 {
		compatible = "alif,dac";
		reg = <0x49029000 0x1000>,
		      <0x49023000 0x100>,
		      <0x1A60A000 0x100>,
		      <0x4902B000 0x100>;
		reg-names = "dac_reg", "cmp_reg", "vbat_reg", "adc_vref";
		alif,reference-mv = <750>; /* DAC12_VREF_CONT=0x4 -> 0.750 V (analog_ctrl.h:41) */
		output_current = "DAC_1200UA_OUT_CUR";
		capacitance = "DAC_8PF_CAPACITANCE";
		status = "disabled";
	};

	/*
	 * CAMERA CAPTURE path -- CPI parallel-camera controller (cam) +
	 * DesignWare MIPI CSI-2 host bridge (csi) + DesignWare MIPI D-PHY (dphy),
	 * all driven by the alp-sdk vendored fork drivers (zephyr/drivers/video/
	 * video_alif.c "alif,cam", video_csi_dw.c "snps,designware-csi",
	 * zephyr/drivers/mipi_dphy/dphy_dw.c "snps,designware-dphy").  reg / IRQ /
	 * reg-names / clock-names are transcribed VERBATIM from the Apache-2.0
	 * zephyr_alif fork e3_e5_e7.dtsi (cam@49030000, csi@49033000) + e1.dtsi
	 * (d-phy@49033000) -- the SAME DesignWare camera IP across the Ensemble
	 * family, identical addresses on E8.
	 *
	 *   cam  : reg 0x49030000/0x1000          IRQ 345  clock-names "cam_clk"
	 *   csi  : reg 0x49033000/0x1000          IRQ 344  clock-names "csi_clk","pix_clk"
	 *   dphy : reg "csi_reg" 0x49033000/0x1000 (shared CSI base),
	 *          "dsi_reg" 0x49032000/0x1000, "expmst_reg" 0x4903f000/0x40
	 *          clock-names "pllref-clk","pllbypass-clk","tx-dphy-clk","rx-dphy-clk"
	 *
	 * CLOCKS -- FLAGGED PLACEHOLDER.  The fork drives these blocks with
	 * ALIF_CPI_CLK / ALIF_CSI_CLK / ALIF_CSI_PIX_SYST_ACLK / ALIF_MIPI_*_CLK,
	 * which exist ONLY in the fork's 7-arg clock encoding.  Per
	 * [[reference_alif_clock_encoding_fork_vs_upstream]] those packed values
	 * MUST NOT be copied onto the upstream alif,clockctrl (wrong register
	 * block).  The upstream-encoding gate/offset/parent for the camera clocks
	 * are a TRM/bench unknown and are NOT re-authored here -- a frequency-only
	 * dummy clock (ALIF_CLK(2U), the ALIF_SPI_CLK precedent) is used so the
	 * nodes are well-formed.  The drivers are now PORTED to the v4.4 video API
	 * (the ALP_VIDEO_ALIF_BROKEN gate is retired), but these camera nodes stay
	 * status="disabled" here -- a board overlay enables them -- and even then NO
	 * real clock is programmed (the dummy clock above).  Re-author the real
	 * camera clock IDs via alif-ensemble-clocks-ext.h when the stack is
	 * bench-brought-up (task #21).
	 *
	 * NO pinctrl-0: the fork cam node references &pinctrl_cam8 (the 8-bit CPI
	 * data pads), not defined in this tree; the driver applies pinctrl only IF
	 * the node carries it, so the node is left pinctrl-less (a board that wires
	 * a parallel sensor adds the group per the Alif TRM).  The CSI/MIPI path
	 * uses serial D-PHY pads (no parallel pinctrl).
	 *
	 * ADR 0017 Tier-2 (fork-driver copies; upstream + hal_alif ship no camera
	 * video / mipi_dphy drivers) -- INTERIM, retires onto the fork once the
	 * nodes are repointed + the drivers ported to the v4.4 video API +
	 * bench-verified (task #21).  Runtime frame CAPTURE is HW-blocked on this
	 * batch (no camera sensor wired).  BENCH-UNVERIFIED.
	 */
	dphy: d-phy@49033000 {
		compatible = "snps,designware-dphy";
		reg = <0x49033000 0x1000>,
		      <0x49032000 0x1000>,
		      <0x4903F000 0x40>;
		reg-names = "csi_reg", "dsi_reg", "expmst_reg";
		#dphy-cells = <1>;
		clocks = <&clockctrl ALIF_CSI_DPHY_CLK>,
			 <&clockctrl ALIF_CSI_DPHY_CLK>,
			 <&clockctrl ALIF_CSI_DPHY_CLK>,
			 <&clockctrl ALIF_CSI_DPHY_CLK>;
		clock-names = "pllref-clk", "pllbypass-clk", "tx-dphy-clk", "rx-dphy-clk";
		ref-frequency = <38400000>;
		cfg-clk-frequency = <25000000>;
		status = "disabled";
	};

	cam: cam@49030000 {
		compatible = "alif,cam";
		reg = <0x49030000 0x1000>;
		interrupts = <345 0>;
		clocks = <&clockctrl ALIF_CPI_CLK>;
		clock-names = "cam_clk";
		fifo-wr-wmark = <0x18>;
		fifo-rd-wmark = <0x08>;
		wait-vsync;
		status = "disabled";
	};

	csi: csi@49033000 {
		compatible = "snps,designware-csi";
		reg = <0x49033000 0x1000>;
		interrupts = <344 0>;
		clocks = <&clockctrl ALIF_CSI_CLK>, <&clockctrl ALIF_CSI_CLK>;
		clock-names = "csi_clk", "pix_clk";
		ipi-mode = "Camera";
		phy-if = <&dphy 1>, <&dphy 0>;
		csi-hsa = <5>;
		csi-hbp = <10>;
		csi-hsd = <280>;
		csi-hact = <560>;
		csi-vsa = <4>;
		csi-vbp = <4>;
		csi-vfp = <4>;
		csi-vact = <560>;
		status = "disabled";
	};

	/*
	 * Alif Ensemble ISP-Pico (Verisilicon ISP Nano "Pico", compatible
	 * "vsi,isp-pico"), driven by the vendored fork driver
	 * zephyr/drivers/video/isp_pico.c.  reg base + IRQs transcribed VERBATIM
	 * from the fork e4_e6_e8.dtsi (isp@49046000, IRQs 367 "isp" / 368
	 * "mi-isp").  Tier-2 OPT-IN -- the driver links the hal_alif libisp
	 * (Vivante) blob (CONFIG_VIDEO_ISP_VSI -> USE_ALIF_ISP_LIB) and is
	 * default n.  Left status="disabled": enabling it needs the libisp
	 * wrapper bumped (FLAGGED hal_alif version mismatch -- see the Kconfig)
	 * + a camera -> isp -> sink media-controller graph (bench-unknown).
	 * BENCH-UNVERIFIED.  Task #21.
	 */
	isp: isp@49046000 {
		compatible = "vsi,isp-pico";
		reg = <0x49046000 0x1000>;
		interrupts = <367 3>, <368 3>;
		interrupt-names = "isp", "mi-isp";
		status = "disabled";
	};

	/*
	 * CAN-FD controller -- CANFD0 (CAST CAN-CTRL IP, compatible "cast,can",
	 * base 0x49036000), bound by the Tier-2 fork driver
	 * zephyr/drivers/can/can_cast.c as a standard Zephyr can_* device.  Upstream
	 * Zephyr's only CAN driver is the Bosch M_CAN (can_mcan.c), whose register
	 * map does NOT match the CAST IP; hal_alif ships no CAN class driver -- so
	 * this fork copy is the only Zephyr can_* device for the part.  The portable
	 * <alp/can.h> backend (src/backends/can/zephyr_drv.c) binds it via the
	 * alp_can0 alias a board overlay supplies.
	 *
	 * reg/IRQ/FD facts transcribed from the fork's e1.dtsi (can@49036000,
	 * IRQ 104) + the Alif DFP CMSIS headers:
	 *   reg[0] 0x49036000 (CANFD0_BASE, soc.h)        -- register block
	 *   reg[1] 0x49037000 (e1.dtsi "can_cnt_reg")     -- CANFD0 counter window
	 *   can-fd-ctrl-reg 0x4902F00C = CLKCTL_PER_SLV(0x4902F000) + CANFD_CTRL(0xC)
	 *   can-fd-bit 20  = CANFD0_CTRL_FD_ENA (sys_ctrl_canfd.h:47, the
	 *                    SOC_FEAT_CANFD0_CANFD1_CTRL=0 / single-CANFD E8 layout)
	 *
	 * clock: ALIF_CANFD0_160M_CLK is re-authored into the UPSTREAM 8-arg
	 * clockctrl encoding in alif-ensemble-clocks-ext.h (the fork's 7-arg packed
	 * value MUST NOT be copied) -- gate CKEN=bit12, src-sel bit16=1 (160 MHz),
	 * in CANFD_CTRL of CLKCTL_PER_SLV.  clock-frequency carries the controller's
	 * input clock for the bit-timing math; the driver's set_rate is a no-op on
	 * our upstream clockctrl, so this value is what the bit-timing uses (confirm
	 * the divided rate vs the Alif TRM).  BENCH-UNVERIFIED.
	 *
	 * A board enables it (status="okay") + supplies pinctrl_can0 + the alp_can0
	 * alias.  Declared disabled here.
	 */
	can0: can@49036000 {
		compatible      = "cast,can";
		reg             = <0x49036000 0x1000>, <0x49037000 0x1000>;
		reg-names       = "can_reg", "can_cnt_reg";
		interrupt-parent = <&nvic>;
		interrupts      = <104 0>;
		interrupt-names = "can_interrupt";
		clocks          = <&clockctrl ALIF_CANFD0_160M_CLK>;
		clock-frequency = <20000000>;
		can-fd;
		can-fd-ctrl-reg = <0x4902F00C>;
		can-fd-bit      = <20>;
		status          = "disabled";
	};

	/*
	 * ARM PL330 DMA controller -- the RTSS-core-LOCAL DMA.  On the E8 (AE822)
	 * each M55 cluster has its OWN PL330: the RTSS-HE core (this SoM's lead core)
	 * sees it as "DMA2", the RTSS-HP core sees its own as "DMA1"; BOTH sit at the
	 * same core-LOCAL register window 0x400C0000 (secure view) / 0x400E0000
	 * (non-secure view).  This node uses the secure-view local base 0x400C0000 --
	 * the address Alif's own PL330 driver instance prints ("Device
	 * dma2@400c0000 initialized", sdk-alif samples/drivers/dma_user_mcode/
	 * README.rst).  (The third controller, the GLOBAL "DMA0" at 0x49080000 sec /
	 * 0x490A0000 ns, is shared/cross-core and is NOT declared here.)
	 *
	 * Bound by UPSTREAM Zephyr v4.4's ARM PL330 driver (drivers/dma/dma_pl330.c,
	 * compatible "arm,dma-pl330") -- pure ADR 0017 Tier-1 (upstream-native): the
	 * standard Zephyr dma_* class device, no vendored / forked code.  The driver
	 * is a POLLING M2M DMA (dma_pl330_wait() spins on the channel-status CS0
	 * register) and uses NO `interrupts` / `clocks` -- the arm,dma-pl330 binding
	 * declares none, and the PL330 register block is always-clocked in the RTSS
	 * core domain.  (The DFP enumerates DMA2_IRQ0..IRQ31 = the 32 per-request
	 * event lines + DMA2_IRQ_ABORT_IRQn=32 in the RTSS-HE local IRQ space, used
	 * only by an IRQ-driven driver; the upstream polling driver needs none.)
	 *
	 * AUTHORITATIVE VALUES (Alif AE822 DFP, Device/soc/AE822FA0E5597/include/
	 * rtss_he/soc.h):
	 *   reg base 0x400C0000  -- DMA2_SEC_BASE (HP-side DMA1_SEC_BASE is the same
	 *                           0x400C0000).
	 *   dma-channels = <8>   -- the PL330 has 8 execution channels: the DFP DMA2
	 *                           register struct arrays DMA2_SEC_DMA_CHANNEL_RT_INFO
	 *                           DMA_CHANNEL_RT_INFO[8] / DMA_RT_CHANNEL_CFG[8]
	 *                           ([0..7]).
	 *
	 * `microcode` (required by arm,dma-pl330.yaml) -- a scratch RAM base the
	 * driver writes the generated per-channel microcode into (mcode_base; each of
	 * the 8 channels gets MICROCODE_SIZE_MAX=0x400 bytes -- dma_pl330.h -- so
	 * 8 * 0x400 = 0x2000).  The PL330 FETCHES that microcode over its own AXI
	 * master, so the region MUST be at a GLOBAL (AXI-visible) address -- NOT a
	 * core-local TCM alias.  Left as a placeholder 0 here so the disabled SoC node
	 * validates; an enabling board overlay sets it to a real carve-out in global
	 * SRAM0 (0x02000000, the sram0 node) AND places the DMA source/destination
	 * buffers there too (same global-address constraint -- the upstream PL330
	 * driver does NOT do the Alif local->global remap that the NPU/ETH paths use;
	 * see the aen-dma-regcheck overlay).
	 *
	 * A board enables this node (status="okay") + sets a real `microcode` address.
	 * ADR 0017 Tier-1 (upstream-native), BENCH-UNVERIFIED.
	 */
	dma2: dma@400c0000 {
		compatible = "arm,dma-pl330";
		reg = <0x400C0000 0x1000>; /* AE822 DFP rtss_he/soc.h: DMA2_SEC_BASE (M55-HE boots secure on the RAM-run) */
		/* AE822 DFP rtss_he/soc.h: DMA2_SEC DMA_CHANNEL_RT_INFO[8]/DMA_RT_CHANNEL_CFG[8] ([0..7]) */
		dma-channels = <8>;
		#dma-cells = <1>;
		/*
		 * microcode: AXI-visible scratch base for the 8*0x400 B generated channel
		 * ucode.  Placeholder 0; an enabling board overlay MUST point this at a
		 * real global-SRAM0 carve-out (the PL330 fetches ucode over AXI -- a
		 * core-local TCM alias is NOT reachable).
		 */
		microcode = <0x0>;
		status = "disabled";
	};

	/*
	 * Secure-Enclave (SE) SERVICE mailboxes -- the RTSS <-> SE Arm MHUv2 pair.
	 * The Apache-2.0 hal_alif SE client (se_services/zephyr/src/se_service.c,
	 * compiled under CONFIG_HAS_ALIF_SE_SERVICES) talks to the SE over these two
	 * mailboxes via Zephyr's IPM API, driven by the alp-sdk in-tree "arm,mhuv2"
	 * IPM driver (zephyr/drivers/ipm/ipm_arm_mhuv2.c, CONFIG_ARM_MHUV2).  The
	 * driver keys its sender/receiver role off interrupt-names "tx"/"rx".
	 *
	 * reg/IRQ transcribed VERBATIM from the Alif zephyr_alif fork
	 * (dts/arm/alif/ensemble/common/e1.dtsi: seservice0r mhu@40040000 IRQ 37
	 * "rx"; seservice0s mhu@40050000 IRQ 38 "tx") -- the same SoC, identical
	 * addresses.  No clocks/pinctrl: the mailboxes are core-internal (no pads, no
	 * peripheral clock gate).  status="disabled" by default; an app overlay okays
	 * the pair + the se_service root node below.  ADR 0017 Tier-2 (INTERIM,
	 * task #21).  BENCH-UNVERIFIED.
	 *
	 * (seservice1r/s @ 0x40060000/0x40070000 IRQ 39/40 are the SE<->second-RTSS
	 * mailboxes; the rtsshp_rtsshe_* MHUs @ 0x40080000.. are inter-RTSS -- neither
	 * is declared here.)
	 */
	seservice0r: mhu@40040000 {
		compatible = "arm,mhuv2";
		reg = <0x40040000 0x1000>;
		interrupts = <37 3>;
		interrupt-names = "rx";
		status = "disabled";
	};

	seservice0s: mhu@40050000 {
		compatible = "arm,mhuv2";
		reg = <0x40050000 0x1000>;
		interrupts = <38 3>;
		interrupt-names = "tx";
		status = "disabled";
	};

	/*
	 * Hardware semaphore (HWSEM) instance 0 -- the first of the 16 Ensemble
	 * HWSEM latches.  An AMP request/release mutual-exclusion latch shared
	 * between the two RTSS cores (M55-HE <-> M55-HP), keyed by a per-core
	 * MASTER ID.  Driven by the alp-sdk in-tree "alif,hwsem" driver
	 * (zephyr/drivers/misc/alif_hwsem/hwsem_alif.c, CONFIG_HWSEM_ALIF).
	 *
	 * reg transcribed CLEAN-ROOM (address only) from the Alif DFP
	 * Device/soc/AE822FA0E5597/include/rtss_he/soc.h:
	 *   HWSEM0_BASE 0x4902E000, struct HWSEM_Type size 0x0C, instance
	 *   stride 0x10 (HWSEM1_BASE 0x4902E010 ..).  size = 0x10 (the per-
	 *   instance stride; the three registers REQ/REL/RST occupy +0x00..+0x0B).
	 * No clocks/pinctrl: the HWSEM block is core-internal (no pads, no
	 * peripheral clock gate).  status="disabled" by default; an app overlay
	 * okays it (see examples/aen/aen-hwsem-regcheck).  ADR 0017
	 * vendor-native custom.  BENCH-UNVERIFIED.
	 *
	 * (HWSEM1..15 @ 0x4902E010..0x4902E0F0 -- the remaining 15 latches -- are
	 * NOT declared here; add a node per latch as AMP locks are partitioned.)
	 */
	hwsem0: hwsem@4902e000 {
		compatible = "alif,hwsem";
		reg = <0x4902e000 0x10>;
		status = "disabled";
	};
};

/*
 * SE-service root node -- ties the tx + rx MHUv2 mailboxes into one logical
 * channel for the hal_alif SE client (se_service.c DEVICE_DT_GET_OR_NULLs both
 * phandles at SYS_INIT).  Fork e1.dtsi root-level "se_service" node; placed at
 * the root (not inside &soc) to match the fork.  status="disabled"; an app
 * overlay okays it alongside the two mailboxes.
 */
&{/} {
	se_service: se_service {
		compatible = "alif,secure-enclave-services";
		mhuv2-send-node = <&seservice0s>;
		mhuv2-recv-node = <&seservice0r>;
		status = "disabled";
	};
};

/*
 * ARX3A0 MIPI CSI-2 sensor (onnn,arx3a0), driven by the vendored fork driver
 * zephyr/drivers/video/arx3a0.c.  Placed as an I2C child of i2c2 (the edge
 * snps,designware-i2c declared above) -- the sensor's control plane is I2C, its
 * pixel plane is the MIPI CSI-2 D-PHY (the &csi/&dphy nodes above).
 *
 * FLAGGED -- BENCH UNKNOWN (do NOT treat as authoritative):
 *   - I2C BUS: which on-SoM/carrier I2C the camera connector routes to on the
 *     AEN801 SoM is unverified; i2c2 is a plausible default, NOT confirmed.
 *   - reg = <0x36>: the ARX3A0's standard 7-bit I2C address; carried as the
 *     part default, NOT verified against the SoM's strap/connector.
 *   - reset-gpios / power-gpios: the sensor RESETn + power-enable pins are NOT
 *     sourced (no SoM camera-connector pinout in scope) -- OMITTED rather than
 *     invented; the driver applies them only IF present.
 * No camera sensor is wired on this hardware batch, so this is staging only.
 */
&i2c2 {
	#address-cells = <1>;
	#size-cells = <0>;

	arx3a0: arx3a0@36 {
		compatible = "onnn,arx3a0";
		reg = <0x36>;
		status = "disabled";
	};
};
